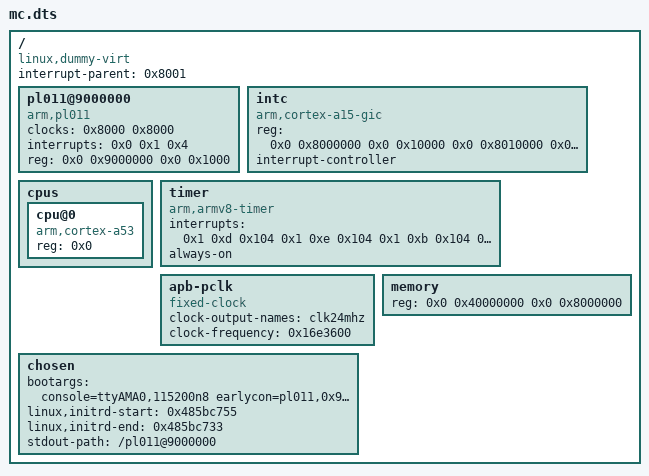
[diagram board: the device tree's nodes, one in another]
/dts-v1/;

/ {
	interrupt-parent = <0x8001>;
	#size-cells = <0x2>;
	#address-cells = <0x2>;
	compatible = "linux,dummy-virt";

	pl011@9000000 {
		clock-names = "uartclk", "apb_pclk";
		clocks = <0x8000 0x8000>;
		interrupts = <0x0 0x1 0x4>;
		reg = <0x0 0x9000000 0x0 0x1000>;
		compatible = "arm,pl011", "arm,primecell";
	};

	// Cf Documentation/devicetree/bindings/interrupt-controller/arm,gic.txt
	intc {
		phandle = <0x8001>;
		reg = <0x0 0x8000000 0x0 0x10000 0x0 0x8010000 0x0 0x10000>;
		compatible = "arm,cortex-a15-gic";
		ranges;
		#size-cells = <0x2>;
		#address-cells = <0x2>;
		interrupt-controller;
		#interrupt-cells = <0x3>;
	};

	cpus {
		#size-cells = <0x0>;
		#address-cells = <0x1>;

		cpu@0 {
			reg = <0x0>;
			compatible = "arm,cortex-a53";
			device_type = "cpu";
		};
	};

	// Cf Documentation/devicetree/bindings/arm/arch_timer.txt
	timer {
	      //  Secure, non-secure, virtual, hypervisor
		interrupts = <0x1 0xd 0x104
		              0x1 0xe 0x104
			      0x1 0xb 0x104
			      0x1 0xa 0x104>;
		always-on;
		compatible = "arm,armv8-timer", "arm,armv7-timer";
	};

	apb-pclk {
		phandle = <0x8000>;
		clock-output-names = "clk24mhz";
		clock-frequency = <0x16e3600>;
		#clock-cells = <0x0>;
		compatible = "fixed-clock";
	};

	memory {
		reg = <0x0 0x40000000 0x0 0x8000000>;
		device_type = "memory";
	};

	chosen {
		bootargs = "console=ttyAMA0,115200n8 earlycon=pl011,0x9000000 loglevel=8";
		/* These are magic numbers that will be patched.... */
		linux,initrd-start = <0x485bc755>;
		linux,initrd-end = <0x485bc733>;
		stdout-path = "/pl011@9000000";
	};
};
